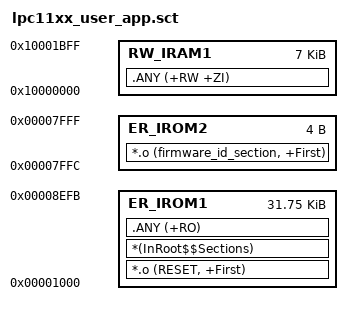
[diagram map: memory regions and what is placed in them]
; *************************************************************
; *** Scatter-Loading Description File generated by uVision ***
; *************************************************************

LR_IROM1 0x00001000 0x00007EFC  {    ; load region size_region
  ER_IROM1 0x00001000 0x00007EFC  {  ; load address = execution address
   *.o (RESET, +First)
   *(InRoot$$Sections)
   .ANY (+RO)
  }
  RW_IRAM1 0x10000000 0x00001C00  {  ; RW data
   .ANY (+RW +ZI)
  }

}
LR_IROM2 0x00007FFC 0x04  {    ; load region size_region
  ER_IROM2 0x00007FFC 0x04  {  ; load address = execution address
   *.o (firmware_id_section, +First)
  }
}

